# captio register map
Vendor: Texas Instruments
Peripheral module from a debugger description file (folder MSP432).
Registers are 16-bit, read-write, no defined reset value unless marked. A register's access mark holds for its fields unless they carry their own. Offsets are as the file gives them; lines under a group give offsets from that group; [hi:lo] are bit positions; {n}, {i} and the like mark numbered series; 'fields as' and 'values as' point back to an identical list; <NAME> marks a mode.

## CAPTIO
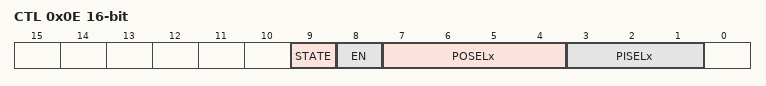
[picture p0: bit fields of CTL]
0x0E CTL — Capacitive Touch IO x Control Register
  [9] STATE — Capacitive Touch IO state
    0=STATE__0 (Curent state 0 or Capacitive Touch IO is disabled); 1=STATE__1 (Current state 1)
  [8] EN — Capacitive Touch IO enable
    0=EN__0 (All Capacitive Touch IOs are disabled); 1=EN__1 (Selected Capacitive Touch IO is enabled)
  [7:4] POSELx — Capacitive Touch IO port select
    0=POSEL__0 (Px = PJ); {v}=POSEL__{v} (Px = P{v}) (v=1..9); {v}=POSEL__{v+6} (Px = P{v}) (v=10..15)
  [3:1] PISELx — Capacitive Touch IO pin select
    0=PISEL__0 (Px.0); 1=PISEL__1 (Px.1); 2=PISEL__2 (Px.2); 3=PISEL__3 (Px.3); 4=PISEL__4 (Px.4); 5=PISEL__5 (Px.5); 6=PISEL__6 (Px.6); 7=PISEL__7 (Px.7)
